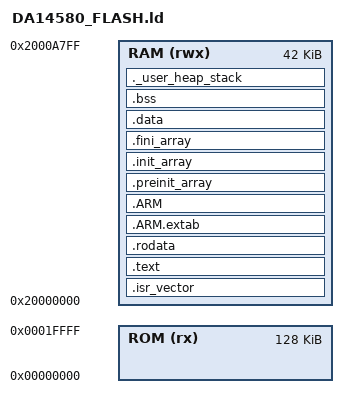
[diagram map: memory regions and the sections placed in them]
/*
Copyright (C) 2013-2017, Fujitsu Electronics Europe GmbH or a               
subsidiary of Fujitsu Electronics Europe GmbH.  All rights reserved.        
                                                                            
This software, including source code, documentation and related             
materials ("Software"), is owned by Fujitsu Electronics Europe GmbH or      
one of its subsidiaries ("Fujitsu").
                                                                            
If no EULA applies, Fujitsu hereby grants you a personal, non-exclusive,    
non-transferable license to copy, modify, and compile the                   
Software source code solely for use in connection with Fujitsu's            
integrated circuit products.  Any reproduction, modification, translation,  
compilation, or representation of this Software except as specified         
above is prohibited without the express written permission of Fujitsu.      
                                                                            
Disclaimer: THIS SOFTWARE IS PROVIDED AS-IS, WITH NO                        
WARRANTY OF ANY KIND, EXPRESS OR IMPLIED, INCLUDING,                        
BUT NOT LIMITED TO, NONINFRINGEMENT, IMPLIED                                
WARRANTIES OF MERCHANTABILITY AND FITNESS FOR A                             
PARTICULAR PURPOSE. Fujitsu reserves the right to make                      
changes to the Software without notice. Fujitsu does not assume any         
liability arising out of the application or use of the Software or any      
product or circuit described in the Software. Fujitsu does not              
authorize its products for use in any products where a malfunction or       
failure of the Fujitsu product may reasonably be expected to result in      
significant property damage, injury or death ("High Risk Product"). By      
including Fujitsu's product in a High Risk Product, the manufacturer        
of such system or application assumes all risk of such use and in doing     
so agrees to indemnify Fujitsu against all liability.                       

*/

/* Entry Point */
ENTRY(Reset_Handler)

/* Highest address of the user mode stack */
_estack = 0x2000A800;    /* end of 42K RAM */

/* Generate a link error if heap and stack don't fit into RAM */
_Min_Heap_Size  = 0x800;    /* required amount of heap  */
_Min_Stack_Size = 0x400; /* required amount of stack */

/* Specify the memory areas */
MEMORY
{
   ROM   (rx)   : ORIGIN = 0x00000000, LENGTH = 128K
   RAM   (rwx)  : ORIGIN = 0x20000000, LENGTH = 42K
}

/* Define output sections */
SECTIONS
{
  /* The startup code goes first into RAM */
  .isr_vector :
  {
    . = ALIGN(4);
    _isr_vector = .;     /* define isr_vector start address */
    KEEP(*(.isr_vector)) /* Startup code */
    . = ALIGN(4);
  } >RAM

  /* The program code and other data goes into RAM */
  .text :
  {
    . = ALIGN(4);
    *(.text)           /* .text sections (code) */
    *(.text*)          /* .text* sections (code) */
    *(.glue_7)         /* glue arm to thumb code */
    *(.glue_7t)        /* glue thumb to arm code */
    *(.eh_frame)

    KEEP (*(.init))
    KEEP (*(.fini))

    . = ALIGN(4);
    _etext = .;        /* define a global symbols at end of code */
  } >RAM

  /* Constant data goes into RAM */
  .rodata :
  {
    . = ALIGN(4);
    *(.rodata)         /* .rodata sections (constants, strings, etc.) */
    *(.rodata*)        /* .rodata* sections (constants, strings, etc.) */
    . = ALIGN(4);
  } >RAM

  .ARM.extab   : { *(.ARM.extab* .gnu.linkonce.armextab.*) } >RAM
  .ARM : {
    __exidx_start = .;
    *(.ARM.exidx*)
    __exidx_end = .;
  } >RAM

  .preinit_array     :
  {
    PROVIDE_HIDDEN (__preinit_array_start = .);
    KEEP (*(.preinit_array*))
    PROVIDE_HIDDEN (__preinit_array_end = .);
  } >RAM
  .init_array :
  {
    PROVIDE_HIDDEN (__init_array_start = .);
    KEEP (*(SORT(.init_array.*)))
    KEEP (*(.init_array*))
    PROVIDE_HIDDEN (__init_array_end = .);
  } >RAM
  .fini_array :
  {
    PROVIDE_HIDDEN (__fini_array_start = .);
    KEEP (*(SORT(.fini_array.*)))
    KEEP (*(.fini_array*))
    PROVIDE_HIDDEN (__fini_array_end = .);
  } >RAM

  /* used by the startup to initialize data */
  _sidata = LOADADDR(.data);
  
  /* Initialized data sections goes into RAM, load LMA copy after code */
  .data : 
  {
    . = ALIGN(4);
    _sdata = .;        /* create a global symbol at data start */
    *(.data)           /* .data sections */
    *(.data*)          /* .data* sections */

    . = ALIGN(4);
    _edata = .;        /* define a global symbol at data end */
  } >RAM

  /* Uninitialized data section */
  . = ALIGN(4);
  .bss :
  {
    /* This is used by the startup in order to initialize the .bss secion */
    _sbss = .;         /* define a global symbol at bss start */
    __bss_start__ = _sbss;
    *(.bss)
    *(.bss*)
    *(COMMON)

    . = ALIGN(4);
    _ebss = .;         /* define a global symbol at bss end */
    __bss_end__ = _ebss;
  } >RAM

  /* User_heap_stack section, used to check that there is enough RAM left */
  ._user_heap_stack :
  {
    . = ALIGN(4);
    PROVIDE ( end = . );
    PROVIDE ( _end = . );
    . = . + _Min_Heap_Size;
    . = . + _Min_Stack_Size;
    . = ALIGN(4);
  } >RAM


  /* Remove information from the standard libraries */
  /DISCARD/ :
  {
    libc.a ( * )
    libm.a ( * )
    libgcc.a ( * )
  }
  
  .ARM.attributes 0 : { *(.ARM.attributes) }
}
